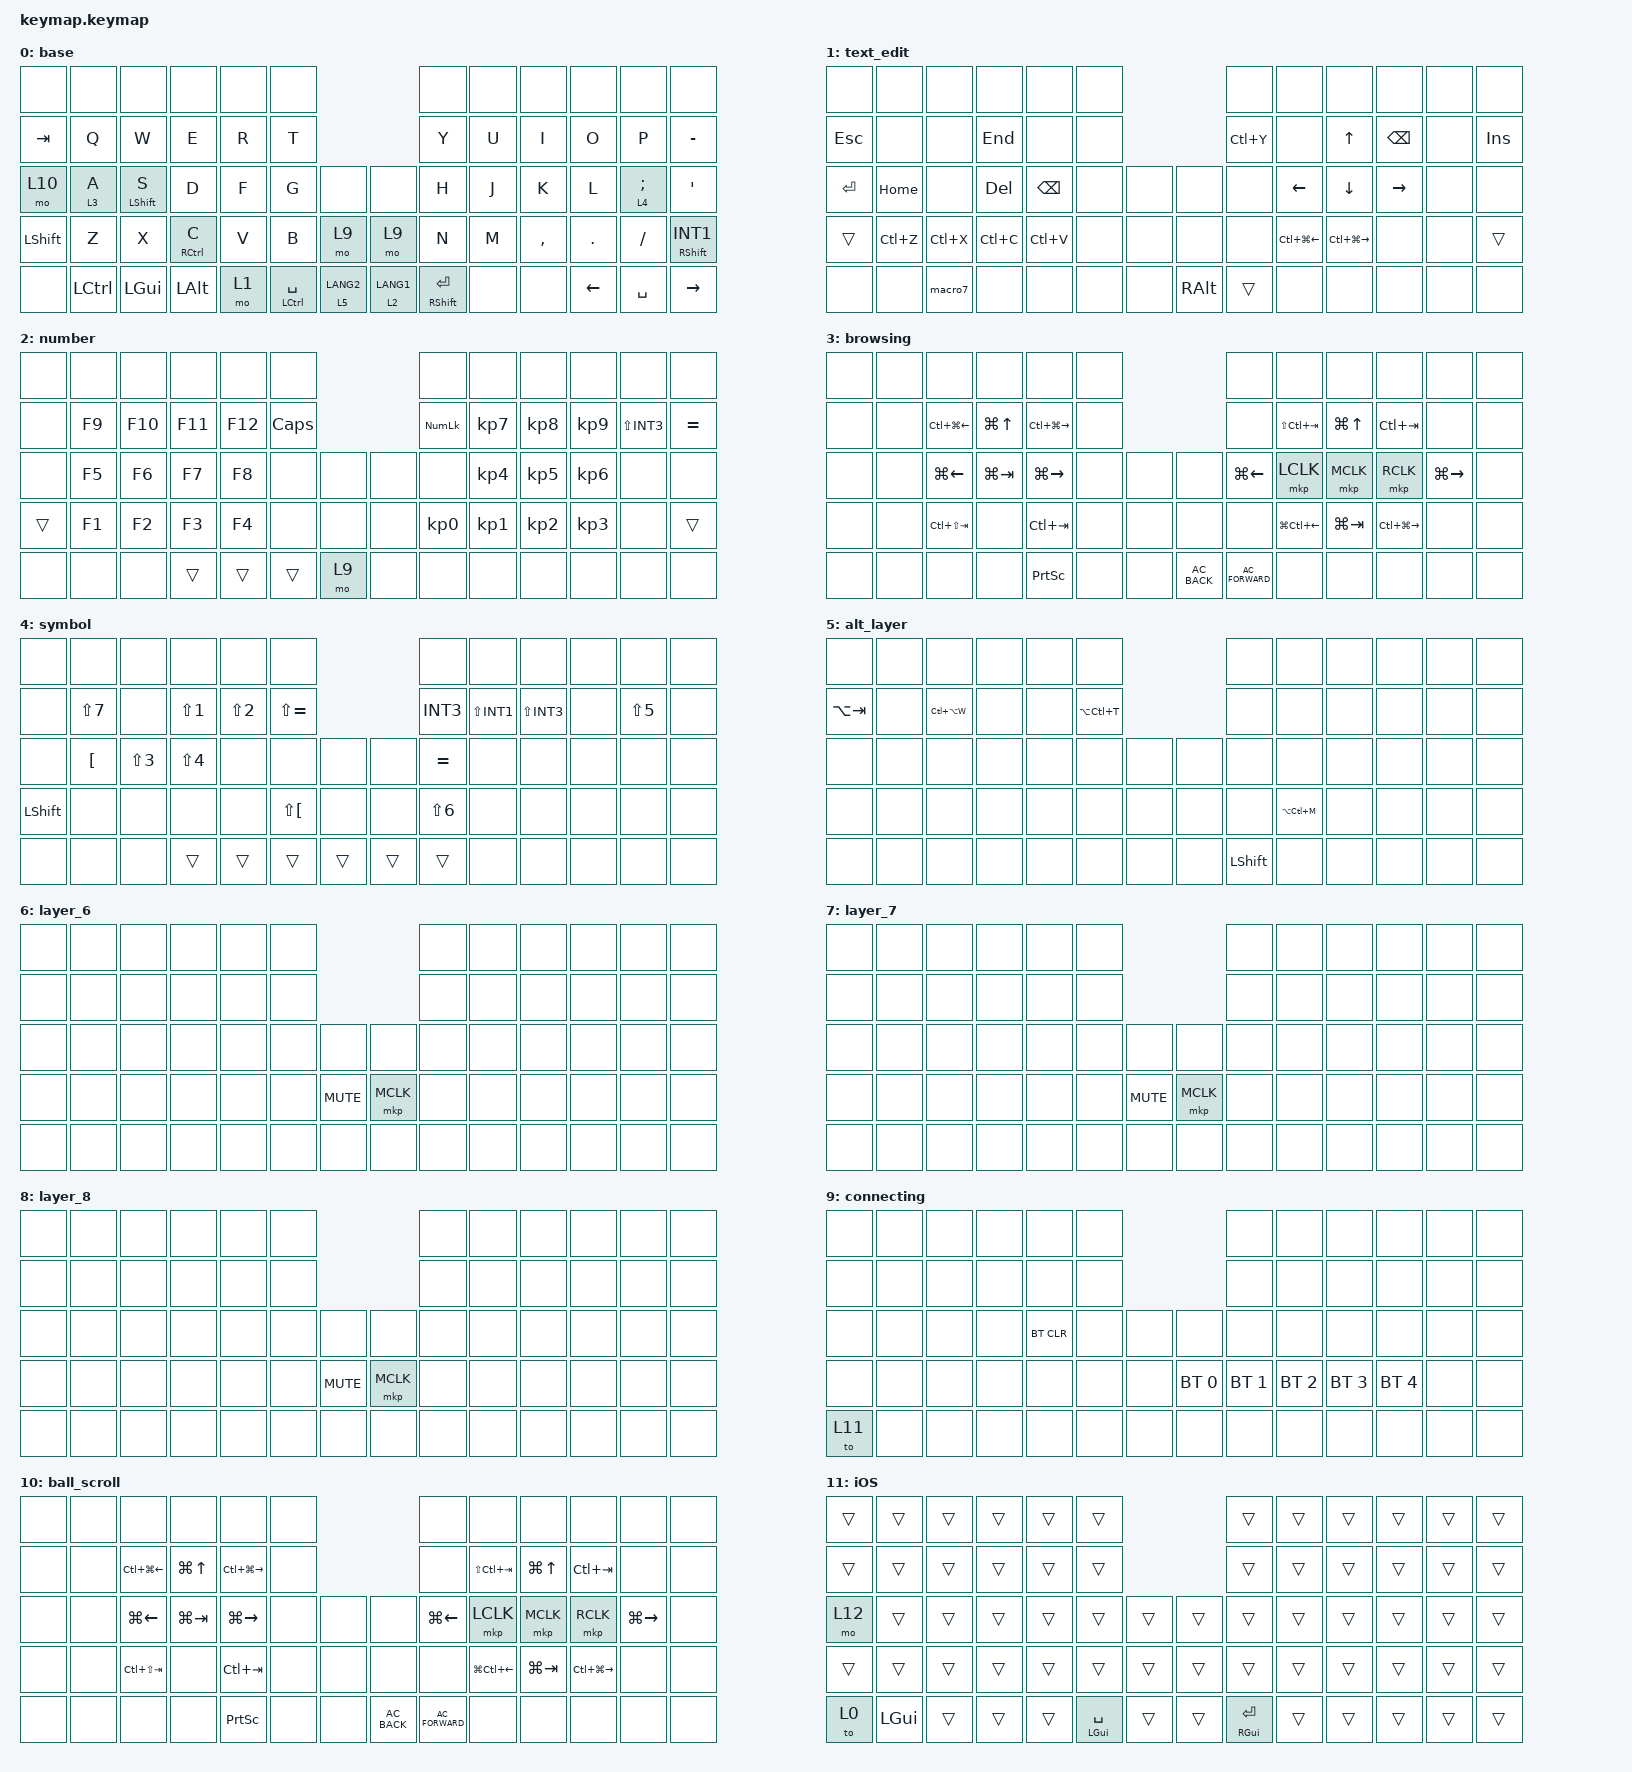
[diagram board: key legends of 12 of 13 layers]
#include <dt-bindings/zmk/behaviors.h>
#include <behaviors.dtsi>
#include <dt-bindings/zmk/bt.h>
#include <dt-bindings/zmk/keys.h>
#include <dt-bindings/zmk/pointing.h>

/*
 * cornix_layout_20260814.vil -> torabo-tsuki LP (M, right trackball)
 *
 * Conversion policy:
 * - Keeps the official torabo-tsuki LP keymap's 66-position L-layout format.
 * - Maps the 50 Cornix bindings onto the 50 populated Choc switches of the
 *   M-size, right-trackball arrangement.
 * - Cornix's right-thumb MO(2) position is moved to the extra innermost key
 *   on the left bottom/thumb row (Torabo logical position 58). This preserves
 *   the three outer right-thumb keys (LEFT / SPACE / RIGHT), while the right
 *   trackball replaces logical positions 61 and 62.
 * - Torabo logical positions 61 and 62 are intentionally left &none.
 * - USER00/01/02/06 cannot be reconstructed from a .vil export and are &none.
 * - M8/M9/M14 are empty in the source .vil and are kept as no-op.
 * - KC_ACL2 (QMK mouse acceleration preset) has no direct ZMK equivalent and
 *   is kept as no-op.
 * - Combo timeout is preserved from Vial QMK Settings (20 ms).
 * - Encoder mappings from the Cornix .vil are not included because
 *   torabo-tsuki LP has no equivalent rotary encoder in this keymap.
 *
 * IMPORTANT:
 * This is a semantic conversion, not a byte-for-byte conversion between QMK
 * and ZMK. Hold/tap timing terms are preserved; interruption behavior uses
 * ZMK's "tap-preferred" flavor, which is closest to QMK's default resolution.
 */

/ {
    behaviors {
        td0: vial_td0_space_lctrl {
            compatible = "zmk,behavior-hold-tap";
            #binding-cells = <2>;
            flavor = "tap-preferred";
            tapping-term-ms = <150>;
            quick-tap-ms = <0>;
            bindings = <&kp>, <&kp>;

            display-name = "TD0 Space/LCTRL";
        };

        td1: vial_td1_semi_layer4 {
            compatible = "zmk,behavior-hold-tap";
            #binding-cells = <2>;
            flavor = "tap-preferred";
            tapping-term-ms = <80>;
            quick-tap-ms = <0>;
            bindings = <&mo>, <&kp>;

            display-name = "TD1 ;/Layer4";
        };

        td2: vial_td2_a_layer3 {
            compatible = "zmk,behavior-hold-tap";
            #binding-cells = <2>;
            flavor = "tap-preferred";
            tapping-term-ms = <150>;
            quick-tap-ms = <0>;
            bindings = <&mo>, <&kp>;

            display-name = "TD2 A/Layer3";
        };

        td3: vial_td3_enter_rctrl {
            compatible = "zmk,behavior-hold-tap";
            #binding-cells = <2>;
            flavor = "tap-preferred";
            tapping-term-ms = <150>;
            quick-tap-ms = <0>;
            bindings = <&kp>, <&kp>;

            display-name = "TD3 Enter/RCTRL";
        };

        td4: vial_td4_enter_layer3 {
            compatible = "zmk,behavior-hold-tap";
            #binding-cells = <2>;
            flavor = "tap-preferred";
            tapping-term-ms = <60>;
            quick-tap-ms = <0>;
            bindings = <&mo>, <&kp>;

            display-name = "TD4 Enter/Layer3";
        };

        td5: vial_td5_lang2_layer5 {
            compatible = "zmk,behavior-hold-tap";
            #binding-cells = <2>;
            flavor = "tap-preferred";
            tapping-term-ms = <100>;
            quick-tap-ms = <0>;
            bindings = <&mo>, <&kp>;

            display-name = "TD5 LANG2/LALT";
        };

        td6: vial_td6_lang1_ralt {
            compatible = "zmk,behavior-hold-tap";
            #binding-cells = <2>;
            flavor = "tap-preferred";
            tapping-term-ms = <100>;
            quick-tap-ms = <0>;
            bindings = <&mo>, <&kp>;

            display-name = "TD6 LANG1/RALT";
        };

        td7: vial_td7_ro_rshift {
            compatible = "zmk,behavior-hold-tap";
            #binding-cells = <2>;
            flavor = "tap-preferred";
            tapping-term-ms = <100>;
            quick-tap-ms = <0>;
            bindings = <&kp>, <&kp>;

            display-name = "TD7 RO/RSHIFT";
        };

        td8: vial_td8_s_lshift {
            compatible = "zmk,behavior-hold-tap";
            #binding-cells = <2>;
            flavor = "tap-preferred";
            tapping-term-ms = <150>;
            quick-tap-ms = <0>;
            bindings = <&kp>, <&kp>;

            display-name = "TD8 S/LSHIFT";
        };

        /* Defined in the .vil but not currently used by any key position. */

        td9: vial_td9_lbracket_lbrace {
            compatible = "zmk,behavior-tap-dance";
            #binding-cells = <0>;
            tapping-term-ms = <81>;
            bindings = <&kp LBKT>, <&kp LS(LBKT)>;

            display-name = "TD9 [/{";
        };

        td10: td10 {
            compatible = "zmk,behavior-hold-tap";
            label = "TD10";
            #binding-cells = <2>;
            bindings = <&kp>, <&kp>;

            tapping-term-ms = <100>;
        };
    };

    macros {
        macro7: vial_macro7 {
            compatible = "zmk,behavior-macro";
            #binding-cells = <0>;
            wait-ms = <30>;
            tap-ms = <30>;
            bindings = <&kp LS(R) &kp LS(B) &kp LS(L) &kp N2 &kp N5 &kp LS(O) &kp N &kp O &kp R &kp EXCL &kp T &kp A &kp I>;
            display-name = "Vial Macro 7";
        };

        ios_macro_right_brace: ios_macro_right_brace {
            compatible = "zmk,behavior-macro";
            #binding-cells = <0>;
            wait-ms = <30>;
            tap-ms = <30>;
            bindings = <&kp Z &kp R &kp SPACE &kp BSPC>;
            display-name = "iOS Text Replacement: Right Brace";
        };
    };

    combos {
        compatible = "zmk,combos";

        combo_df_star {
            timeout-ms = <20>;
            key-positions = <27 28>;
            bindings = <&kp LS(N8)>;
            layers = <0>;
        };

        combo_jk_lparen {
            timeout-ms = <20>;
            key-positions = <33 34>;
            bindings = <&kp LS(N9)>;
            layers = <0>;
        };

        combo_cv_rbracket {
            timeout-ms = <20>;
            key-positions = <42 41>;
            bindings = <&kp RBKT>;
            layers = <0>;
        };

        combo_er_rbrace {
            timeout-ms = <20>;
            key-positions = <15 16>;
            bindings = <&kp LS(RBKT)>;
            layers = <0>;
        };

        combo_ui_shift_nuhs {
            timeout-ms = <20>;
            key-positions = <19 20>;
            bindings = <&kp LS(NUHS)>;
            layers = <0>;
        };

        combo_mt_lbracket {
            timeout-ms = <20>;
            key-positions = <47 48>;
            bindings = <&kp NUHS>;
            layers = <0>;
        };

        /* iOS Japanese input combinations (layer 11 only). */

        combo_df_lparen_ios {
            timeout-ms = <20>;
            key-positions = <27 28>;
            bindings = <&kp LS(N9)>;
            layers = <11>;
        };

        combo_jk_rparen_ios {
            timeout-ms = <20>;
            key-positions = <33 34>;
            bindings = <&kp LS(N0)>;
            layers = <11>;
        };

        combo_cv_lcorner_ios {
            timeout-ms = <20>;
            key-positions = <42 41>;
            bindings = <&kp LBKT>;
            layers = <11>;
        };

        combo_er_lbrace_ios {
            timeout-ms = <20>;
            key-positions = <15 16>;
            bindings = <&kp LS(LBKT)>;
            layers = <11>;
        };

        combo_ui_rbrace_ios {
            timeout-ms = <20>;
            key-positions = <19 20>;
            bindings = <&ios_macro_right_brace>;
            layers = <11>;
        };

        combo_mcomma_rcorner_ios {
            timeout-ms = <20>;
            key-positions = <47 48>;
            bindings = <&kp RBKT>;
            layers = <11>;
        };
    };

    keymap {
        compatible = "zmk,keymap";

        base {
            bindings = <
&none       &none      &none          &none          &none  &none                                         &none                   &none  &none      &none     &none        &none
&kp TAB     &kp Q      &kp W          &kp E          &kp R  &kp T                                         &kp Y                   &kp U  &kp I      &kp O     &kp P        &kp MINUS
&mo 10      &td2 3 A   &td8 LSHIFT S  &kp D          &kp F  &kp G             &none         &none         &kp H                   &kp J  &kp K      &kp L     &td1 4 SEMI  &kp SQT
&kp LSHIFT  &kp Z      &kp X          &td10 RCTRL C  &kp V  &kp B             &mo 9         &mo 9         &kp N                   &kp M  &kp COMMA  &kp DOT   &kp FSLH     &td7 RSHIFT INT1
&none       &kp LCTRL  &kp LGUI       &kp LALT       &mo 1  &td0 LCTRL SPACE  &td5 5 LANG2  &td6 2 LANG1  &td3 RIGHT_SHIFT ENTER  &none  &none      &kp LEFT  &kp SPACE    &kp RIGHT
            >;
        };

        text_edit {
            bindings = <
&none      &none      &none      &none      &none      &none                   &none      &none             &none              &none      &none  &none
&kp ESC    &none      &none      &kp END    &none      &none                   &kp LC(Y)  &none             &kp UP             &kp BSPC   &none  &kp INS
&kp ENTER  &kp HOME   &none      &kp DEL    &kp BSPC   &none  &none  &none     &none      &kp LEFT          &kp DOWN           &kp RIGHT  &none  &none
&trans     &kp LC(Z)  &kp LC(X)  &kp LC(C)  &kp LC(V)  &none  &none  &none     &none      &kp LC(LG(LEFT))  &kp LC(LG(RIGHT))  &none      &none  &trans
&none      &none      &macro7    &none      &none      &none  &none  &kp RALT  &trans     &none             &none              &none      &none  &none
            >;
        };

        number {
            bindings = <
&none   &none   &none    &none    &none    &none                   &none           &none      &none      &none      &none         &none
&none   &kp F9  &kp F10  &kp F11  &kp F12  &kp CAPS                &kp KP_NUMLOCK  &kp KP_N7  &kp KP_N8  &kp KP_N9  &kp LS(INT3)  &kp EQUAL
&none   &kp F5  &kp F6   &kp F7   &kp F8   &none     &none  &none  &none           &kp KP_N4  &kp KP_N5  &kp KP_N6  &none         &none
&trans  &kp F1  &kp F2   &kp F3   &kp F4   &none     &none  &none  &kp KP_N0       &kp KP_N1  &kp KP_N2  &kp KP_N3  &none         &trans
&none   &none   &none    &trans   &trans   &trans    &mo 9  &none  &none           &none      &none      &none      &none         &none
            >;
        };

        browsing {
            bindings = <
&none  &none  &none             &none        &none              &none                        &none             &none             &none             &none              &none          &none
&none  &none  &kp LC(LG(LEFT))  &kp LG(UP)   &kp LC(LG(RIGHT))  &none                        &none             &kp LS(LC(TAB))   &kp LG(UP_ARROW)  &kp LC(TAB)        &none          &none
&none  &none  &kp LG(LEFT)      &kp LG(TAB)  &kp LG(RIGHT)      &none  &none  &none          &kp LG(LEFT)      &mkp LCLK         &mkp MCLK         &mkp RCLK          &kp LG(RIGHT)  &none
&none  &none  &kp LC(LS(TAB))   &none        &kp LC(TAB)        &none  &none  &none          &none             &kp LG(LC(LEFT))  &kp LG(TAB)       &kp LC(LG(RIGHT))  &none          &none
&none  &none  &none             &none        &kp PSCRN          &none  &none  &kp C_AC_BACK  &kp C_AC_FORWARD  &none             &none             &none              &none          &none
            >;
        };

        symbol {
            bindings = <
&none       &none       &none       &none       &none       &none                          &none       &none         &none         &none  &none       &none
&none       &kp LS(N7)  &none       &kp LS(N1)  &kp LS(N2)  &kp LS(EQUAL)                  &kp INT3    &kp LS(INT1)  &kp LS(INT3)  &none  &kp LS(N5)  &none
&none       &kp LBKT    &kp LS(N3)  &kp LS(N4)  &none       &none          &none   &none   &kp EQUAL   &none         &none         &none  &none       &none
&kp LSHIFT  &none       &none       &none       &none       &kp LS(LBKT)   &none   &none   &kp LS(N6)  &none         &none         &none  &none       &none
&none       &none       &none       &trans      &trans      &trans         &trans  &trans  &trans      &none         &none         &none  &none       &none
            >;
        };

        alt_layer {
            bindings = <
&none        &none  &none          &none  &none  &none                        &none           &none          &none  &none  &none  &none
&kp LA(TAB)  &none  &kp LC(LA(W))  &none  &none  &kp LA(LC(T))                &none           &none          &none  &none  &none  &none
&none        &none  &none          &none  &none  &none          &none  &none  &none           &none          &none  &none  &none  &none
&none        &none  &none          &none  &none  &none          &none  &none  &none           &kp LA(LC(M))  &none  &none  &none  &none
&none        &none  &none          &none  &none  &none          &none  &none  &kp LEFT_SHIFT  &none          &none  &none  &none  &none
            >;
        };

        layer_6 {
            bindings = <
&none  &none  &none  &none  &none  &none                         &none  &none  &none  &none  &none  &none
&none  &none  &none  &none  &none  &none                         &none  &none  &none  &none  &none  &none
&none  &none  &none  &none  &none  &none  &none       &none      &none  &none  &none  &none  &none  &none
&none  &none  &none  &none  &none  &none  &kp C_MUTE  &mkp MCLK  &none  &none  &none  &none  &none  &none
&none  &none  &none  &none  &none  &none  &none       &none      &none  &none  &none  &none  &none  &none
            >;
        };

        layer_7 {
            bindings = <
&none  &none  &none  &none  &none  &none                         &none  &none  &none  &none  &none  &none
&none  &none  &none  &none  &none  &none                         &none  &none  &none  &none  &none  &none
&none  &none  &none  &none  &none  &none  &none       &none      &none  &none  &none  &none  &none  &none
&none  &none  &none  &none  &none  &none  &kp C_MUTE  &mkp MCLK  &none  &none  &none  &none  &none  &none
&none  &none  &none  &none  &none  &none  &none       &none      &none  &none  &none  &none  &none  &none
            >;
        };

        layer_8 {
            bindings = <
&none  &none  &none  &none  &none  &none                         &none  &none  &none  &none  &none  &none
&none  &none  &none  &none  &none  &none                         &none  &none  &none  &none  &none  &none
&none  &none  &none  &none  &none  &none  &none       &none      &none  &none  &none  &none  &none  &none
&none  &none  &none  &none  &none  &none  &kp C_MUTE  &mkp MCLK  &none  &none  &none  &none  &none  &none
&none  &none  &none  &none  &none  &none  &none       &none      &none  &none  &none  &none  &none  &none
            >;
        };

        connecting {
            bindings = <
&none   &none  &none  &none  &none       &none                       &none         &none         &none         &none         &none  &none
&none   &none  &none  &none  &none       &none                       &none         &none         &none         &none         &none  &none
&none   &none  &none  &none  &bt BT_CLR  &none  &none  &none         &none         &none         &none         &none         &none  &none
&none   &none  &none  &none  &none       &none  &none  &bt BT_SEL 0  &bt BT_SEL 1  &bt BT_SEL 2  &bt BT_SEL 3  &bt BT_SEL 4  &none  &none
&to 11  &none  &none  &none  &none       &none  &none  &none         &none         &none         &none         &none         &none  &none
            >;
        };

        /* Keeps the normal key bindings available while the scroll layer is held. */

        ball_scroll {
            bindings = <
&none  &none  &none             &none        &none              &none                        &none             &none             &none             &none              &none          &none
&none  &none  &kp LC(LG(LEFT))  &kp LG(UP)   &kp LC(LG(RIGHT))  &none                        &none             &kp LS(LC(TAB))   &kp LG(UP_ARROW)  &kp LC(TAB)        &none          &none
&none  &none  &kp LG(LEFT)      &kp LG(TAB)  &kp LG(RIGHT)      &none  &none  &none          &kp LG(LEFT)      &mkp LCLK         &mkp MCLK         &mkp RCLK          &kp LG(RIGHT)  &none
&none  &none  &kp LC(LS(TAB))   &none        &kp LC(TAB)        &none  &none  &none          &none             &kp LG(LC(LEFT))  &kp LG(TAB)       &kp LC(LG(RIGHT))  &none          &none
&none  &none  &none             &none        &kp PSCRN          &none  &none  &kp C_AC_BACK  &kp C_AC_FORWARD  &none             &none             &none              &none          &none
            >;
        };

        /* iOS overlay: use Command in the physical Ctrl positions. */

        iOS {
            bindings = <
&trans  &trans    &trans  &trans  &trans  &trans                           &trans           &trans  &trans  &trans  &trans  &trans
&trans  &trans    &trans  &trans  &trans  &trans                           &trans           &trans  &trans  &trans  &trans  &trans
&mo 12  &trans    &trans  &trans  &trans  &trans           &trans  &trans  &trans           &trans  &trans  &trans  &trans  &trans
&trans  &trans    &trans  &trans  &trans  &trans           &trans  &trans  &trans           &trans  &trans  &trans  &trans  &trans
&to 0   &kp LGUI  &trans  &trans  &trans  &td0 LGUI SPACE  &trans  &trans  &td3 RGUI ENTER  &trans  &trans  &trans  &trans  &trans
            >;
        };

        /* iOS-only scroll layer: same keys as ball_scroll, with slower scrolling below. */

        ios_ball_scroll {
            bindings = <
&none  &none  &none             &none        &none              &none                        &none             &none             &none             &none              &none          &none
&none  &none  &kp LC(LG(LEFT))  &kp LG(UP)   &kp LC(LG(RIGHT))  &none                        &none             &kp LS(LC(TAB))   &kp LG(UP_ARROW)  &kp LC(TAB)        &none          &none
&none  &none  &kp LG(LEFT)      &kp LG(TAB)  &kp LG(RIGHT)      &none  &none  &none          &kp LG(LEFT)      &mkp LCLK         &mkp MCLK         &mkp RCLK          &kp LG(RIGHT)  &none
&none  &none  &kp LC(LS(TAB))   &none        &kp LC(TAB)        &none  &none  &none          &none             &kp LG(LC(LEFT))  &kp LG(TAB)       &kp LC(LG(RIGHT))  &none          &none
&none  &none  &none             &none        &kp PSCRN          &none  &none  &kp C_AC_BACK  &kp C_AC_FORWARD  &none             &none             &none              &none          &none
            >;
        };
    };
};

&pointing_listener {
    scroll_layer {
        layers = <10>;
        input-processors =
            <&zip_xy_transform INPUT_TRANSFORM_X_INVERT>,
            <&zip_xy_to_scroll_mapper>;
    };

    ios_scroll_layer {
        layers = <12>;
        input-processors =
            <&zip_xy_transform INPUT_TRANSFORM_X_INVERT>,
            <&zip_xy_to_scroll_mapper>,
            <&zip_scroll_scaler 1 20>;
    };
};
